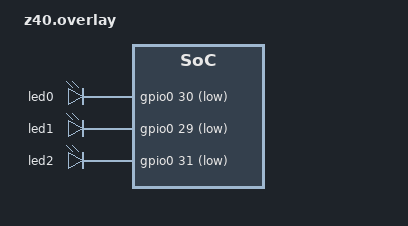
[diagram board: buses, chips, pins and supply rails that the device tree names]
/ {
    aliases {
        led-red = &led0;
        led-green = &led1;
        led-blue = &led2;
    };

    leds {
        compatible = "gpio-leds";
        status = "okay";
        led0: led_0 {
            gpios = <&gpio0 30 GPIO_ACTIVE_LOW>;  // red LED
        };
        led1: led_1 {
            gpios = <&gpio0 29 GPIO_ACTIVE_LOW>;  // green LED
        };
        led2: led_2 {
            gpios = <&gpio0 31 GPIO_ACTIVE_LOW>;  // blue LED
        };
    };
};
